# CC1312PSIP register map
File version: 1.0
CPU: CM4 1.0, other endian, MPU, FPU, 3 interrupt priority bits
Registers are 32-bit, read-write, reset 0x0 unless marked. A register's access mark holds for its fields unless they carry their own. Offsets are from the block's base; [hi:lo] are bit positions; 'fields as' and 'values as' point back to an identical list.

## AON_BATMON — Always On (AON) Battery And Temperature MONitor (BATMON) residing in the AON domain Note: This module only supports 32 bit Read/Write access from MCU.
Base 0x40095000
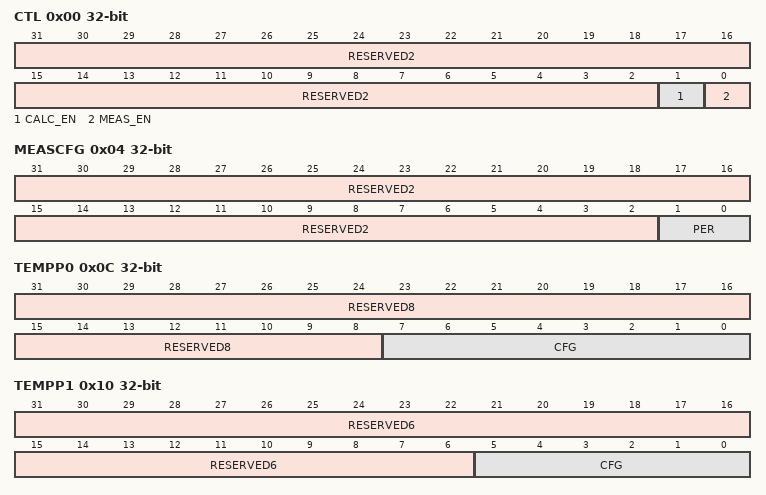
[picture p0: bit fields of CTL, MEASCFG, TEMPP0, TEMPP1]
0x00 CTL — Internal. Only to be used through TI provided API.
  [31:2] RESERVED2 ro — [31:2] Internal. Only to be used through TI provided API.
  [1] CALC_EN — [1:1] Internal. Only to be used through TI provided API.
  [0] MEAS_EN — [0:0] Internal. Only to be used through TI provided API.
0x04 MEASCFG — Internal. Only to be used through TI provided API.
  [31:2] RESERVED2 ro — [31:2] Internal. Only to be used through TI provided API.
  [1:0] PER — [1:0] Internal. Only to be used through TI provided API.
    3=32CYC (Internal. Only to be used through TI provided API.); 2=16CYC (Internal. Only to be used through TI provided API.); 1=8CYC (Internal. Only to be used through TI provided API.); 0=CONT (Internal. Only to be used through TI provided API.)
0x0C TEMPP0 — Internal. Only to be used through TI provided API.
  [31:8] RESERVED8 ro — [31:8] Internal. Only to be used through TI provided API.
  [7:0] CFG — [7:0] Internal. Only to be used through TI provided API.
0x10 TEMPP1 — Internal. Only to be used through TI provided API.
  [31:6] RESERVED6 ro — [31:6] Internal. Only to be used through TI provided API.
  [5:0] CFG — [5:0] Internal. Only to be used through TI provided API.
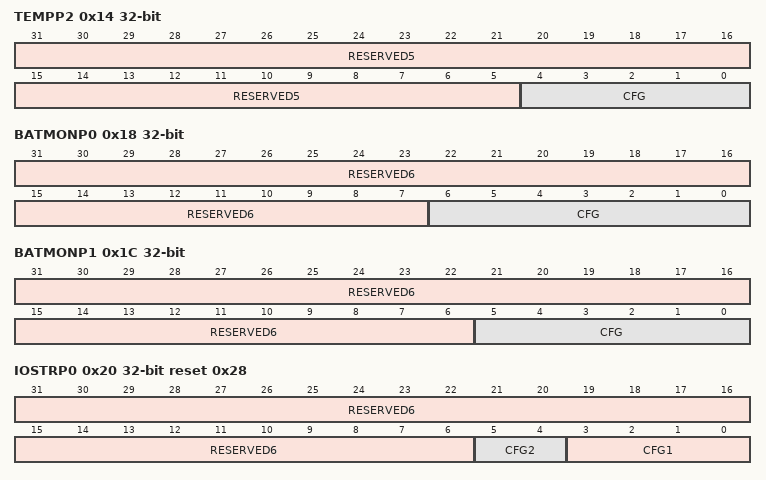
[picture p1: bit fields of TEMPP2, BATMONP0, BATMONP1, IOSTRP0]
0x14 TEMPP2 — Internal. Only to be used through TI provided API.
  [31:5] RESERVED5 ro — [31:5] Internal. Only to be used through TI provided API.
  [4:0] CFG — [4:0] Internal. Only to be used through TI provided API.
0x18 BATMONP0 — Internal. Only to be used through TI provided API.
  [31:7] RESERVED6 ro — [31:7] Internal. Only to be used through TI provided API.
  [6:0] CFG — [6:0] Internal. Only to be used through TI provided API.
0x1C BATMONP1 — Internal. Only to be used through TI provided API.
  fields as TEMPP1
0x20 IOSTRP0 reset 0x28 — Internal. Only to be used through TI provided API.
  [31:6] RESERVED6 ro — [31:6] Internal. Only to be used through TI provided API.
  [5:4] CFG2 — [5:4] Internal. Only to be used through TI provided API.
  [3:0] CFG1 — [3:0] Internal. Only to be used through TI provided API.
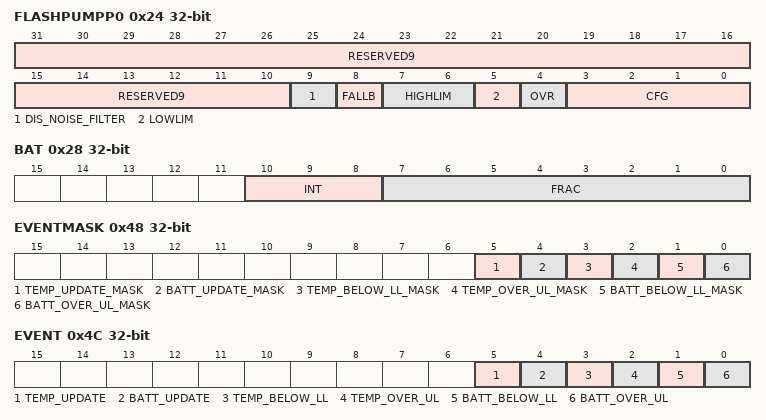
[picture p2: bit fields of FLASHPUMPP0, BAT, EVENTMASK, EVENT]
0x24 FLASHPUMPP0 — Internal. Only to be used through TI provided API.
  [31:10] RESERVED9 ro — [31:10] Internal. Only to be used through TI provided API.
  [9] DIS_NOISE_FILTER — [9:9] Internal. Only to be used through TI provided API.
  [8] FALLB — [8:8] Internal. Only to be used through TI provided API.
  [7:6] HIGHLIM — [7:6] Internal. Only to be used through TI provided API.
  [5] LOWLIM — [5:5] Internal. Only to be used through TI provided API.
  [4] OVR — [4:4] Internal. Only to be used through TI provided API.
  [3:0] CFG — [3:0] Internal. Only to be used through TI provided API.
0x28 BAT — Last Measured Battery Voltage This register may be read while BATUPD.STAT = 1
  [10:8] INT ro — [10:8] Integer part: 0x0: 0V + fractional part ... 0x3: 3V + fractional part 0x4: 4V + fractional part
  [7:0] FRAC ro — [7:0] Fractional part, standard binary fractional encoding. 0x00: .0V ... 0x20: 1/8 = .125V 0x40: 1/4 = .25V 0x80: 1/2 = .5V ... 0xA0: 1/2 + 1/8 = .625V ... 0xFF: Max
0x2C BATUPD — Battery Update Indicates BAT Updates
  [0] STAT — [0:0] 0: No update since last clear 1: New battery voltage is present. Write 1 to clear the status.
0x30 TEMP — Temperature Last Measured Temperature in Degrees Celsius This register may be read while TEMPUPD.STAT = 1.
  [16:8] INT ro — [16:8] Integer part (signed) of temperature value. Total value = INTEGER + FRACTIONAL 2's complement encoding 0x100: Min value 0x1D8: -40C 0x1FF: -1C 0x00: 0C 0x1B: 27C 0x55: 85C 0xFF: Max value
0x34 TEMPUPD — Temperature Update Indicates TEMP Updates
  [0] STAT — [0:0] 0: No update since last clear 1: New temperature is present. Write 1 to clear the status.
0x48 EVENTMASK
  [5] TEMP_UPDATE_MASK — [5:5] 1: EVENT.TEMP_UPDATE contributes to combined event from BATMON 0: EVENT.TEMP_UPDATE does not contribute to combined event from BATMON
  [4] BATT_UPDATE_MASK — [4:4] 1: EVENT.BATT_UPDATE contributes to combined event from BATMON 0: EVENT.BATT_UPDATE does not contribute to combined event from BATMON
  [3] TEMP_BELOW_LL_MASK — [3:3] 1: EVENT.TEMP_BELOW_LL contributes to combined event from BATMON 0: EVENT.TEMP_BELOW_LL does not contribute to combined event from BATMON
  [2] TEMP_OVER_UL_MASK — [2:2] 1: EVENT.TEMP_OVER_UL contributes to combined event from BATMON 0: EVENT.TEMP_OVER_UL does not contribute to combined event from BATMON
  [1] BATT_BELOW_LL_MASK — [1:1] 1: EVENT.BATT_BELOW_LL contributes to combined event from BATMON 0: EVENT.BATT_BELOW_LL does not contribute to combined event from BATMON
  [0] BATT_OVER_UL_MASK — [0:0] 1: EVENT.BATT_OVER_UL contributes to combined event from BATMON 0: EVENT.BATT_OVER_UL does not contribute to combined event from BATMON
0x4C EVENT
  [5] TEMP_UPDATE — [5:5] Alias to TEMPUPD.STAT
  [4] BATT_UPDATE — [4:4] Alias to BATUPD.STAT
  [3] TEMP_BELOW_LL — [3:3] Read: 1: Temperature level is below the lower limit set by TEMPLL. 0: Temperature level is not below the lower limit set by TEMPLL. Write: 1: Clears the flag 0: No change in the flag
  [2] TEMP_OVER_UL — [2:2] Read: 1: Temperature level is above the upper limit set by TEMPUL. 0: Temperature level is not above the upper limit set by TEMPUL. Write: 1: Clears the flag 0: No change in the flag
  [1] BATT_BELOW_LL — [1:1] Read: 1: Battery level is below the lower limit set by BATTLL. 0: Battery level is not below the lower limit set by BATTLL. Write: 1: Clears the flag 0: No change in the flag
  [0] BATT_OVER_UL — [0:0] Read: 1: Battery level is above the upper limit set by BATTUL. 0: Battery level is not above the upper limit set by BATTUL. Write: 1: Clears the flag 0: No change in the flag
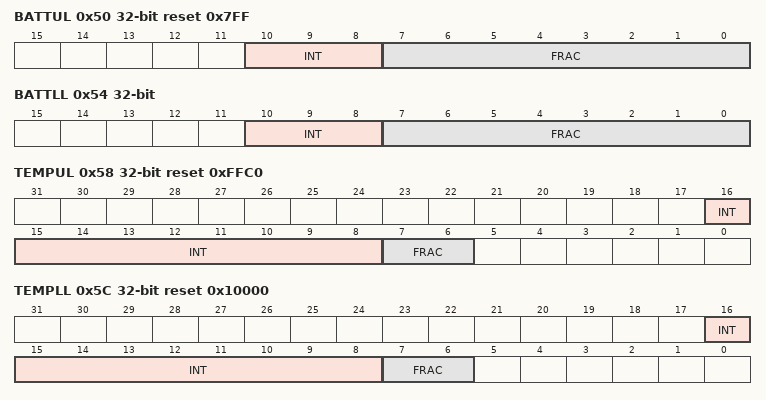
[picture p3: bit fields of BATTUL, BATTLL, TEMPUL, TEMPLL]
0x50 BATTUL reset 0x7FF — Battery Upper Limit
  [10:8] INT — [10:8] Integer part: 0x0: 0V + fractional part ... 0x3: 3V + fractional part 0x4: 4V + fractional part
  [7:0] FRAC — [7:0] Fractional part, standard binary fractional encoding. 0x00: .0V ... 0x20: 1/8 = .125V 0x40: 1/4 = .25V 0x80: 1/2 = .5V ... 0xA0: 1/2 + 1/8 = .625V ... 0xFF: Max
0x54 BATTLL — Battery Lower Limit
  fields as BATTUL
0x58 TEMPUL reset 0xFFC0 — Temperature Upper Limit
  [16:8] INT — [16:8] Integer part (signed) of temperature upper limit. Total value = INTEGER + FRACTIONAL 2's complement encoding 0x100: Min value 0x1D8: -40C 0x1FF: -1C 0x00: 0C 0x1B: 27C 0x55: 85C 0xFF: Max value
  [7:6] FRAC — [7:6] Fractional part of temperature upper limit. Total value = INTEGER + FRACTIONAL The encoding is an extension of the 2's complement encoding. 00: 0.0C 01: 0.25C 10: 0.5C 11: 0.75C For example: 000000001,00 = ( 1+0,00) = 1,00 000000000,11 = ( 0+0,75) = 0,75 000000000,10 = ( 0+0,50) = 0,50 000000000,01 = ( 0+0,25) = 0,25 000000000,00 = ( 0+0,00) = 0,00 111111111,11 = (-1+0,75) = -0,25 111111111,10 = (-1+0,50) = -0,50 111111111,01 = (-1+0,25) = -0,75 111111111,00 = (-1+0,00) = -1,00 111111110,11 = (-2+0,75) = -1,25
0x5C TEMPLL reset 0x10000 — Temperature Lower Limit
  [16:8] INT — [16:8] Integer part (signed) of temperature lower limit. Total value = INTEGER + FRACTIONAL 2's complement encoding 0x100: Min value 0x1D8: -40C 0x1FF: -1C 0x00: 0C 0x1B: 27C 0x55: 85C 0xFF: Max value
  [7:6] FRAC — [7:6] Fractional part of temperature lower limit. Total value = INTEGER + FRACTIONAL The encoding is an extension of the 2's complement encoding. 00: 0.0C 01: 0.25C 10: 0.5C 11: 0.75C For example: 000000001,00 = ( 1+0,00) = 1,00 000000000,11 = ( 0+0,75) = 0,75 000000000,10 = ( 0+0,50) = 0,50 000000000,01 = ( 0+0,25) = 0,25 000000000,00 = ( 0+0,00) = 0,00 111111111,11 = (-1+0,75) = -0,25 111111111,10 = (-1+0,50) = -0,50 111111111,01 = (-1+0,25) = -0,75 111111111,00 = (-1+0,00) = -1,00 111111110,11 = (-2+0,75) = -1,25
